AUTOSAR XML (schema 00045)
package /Dsm
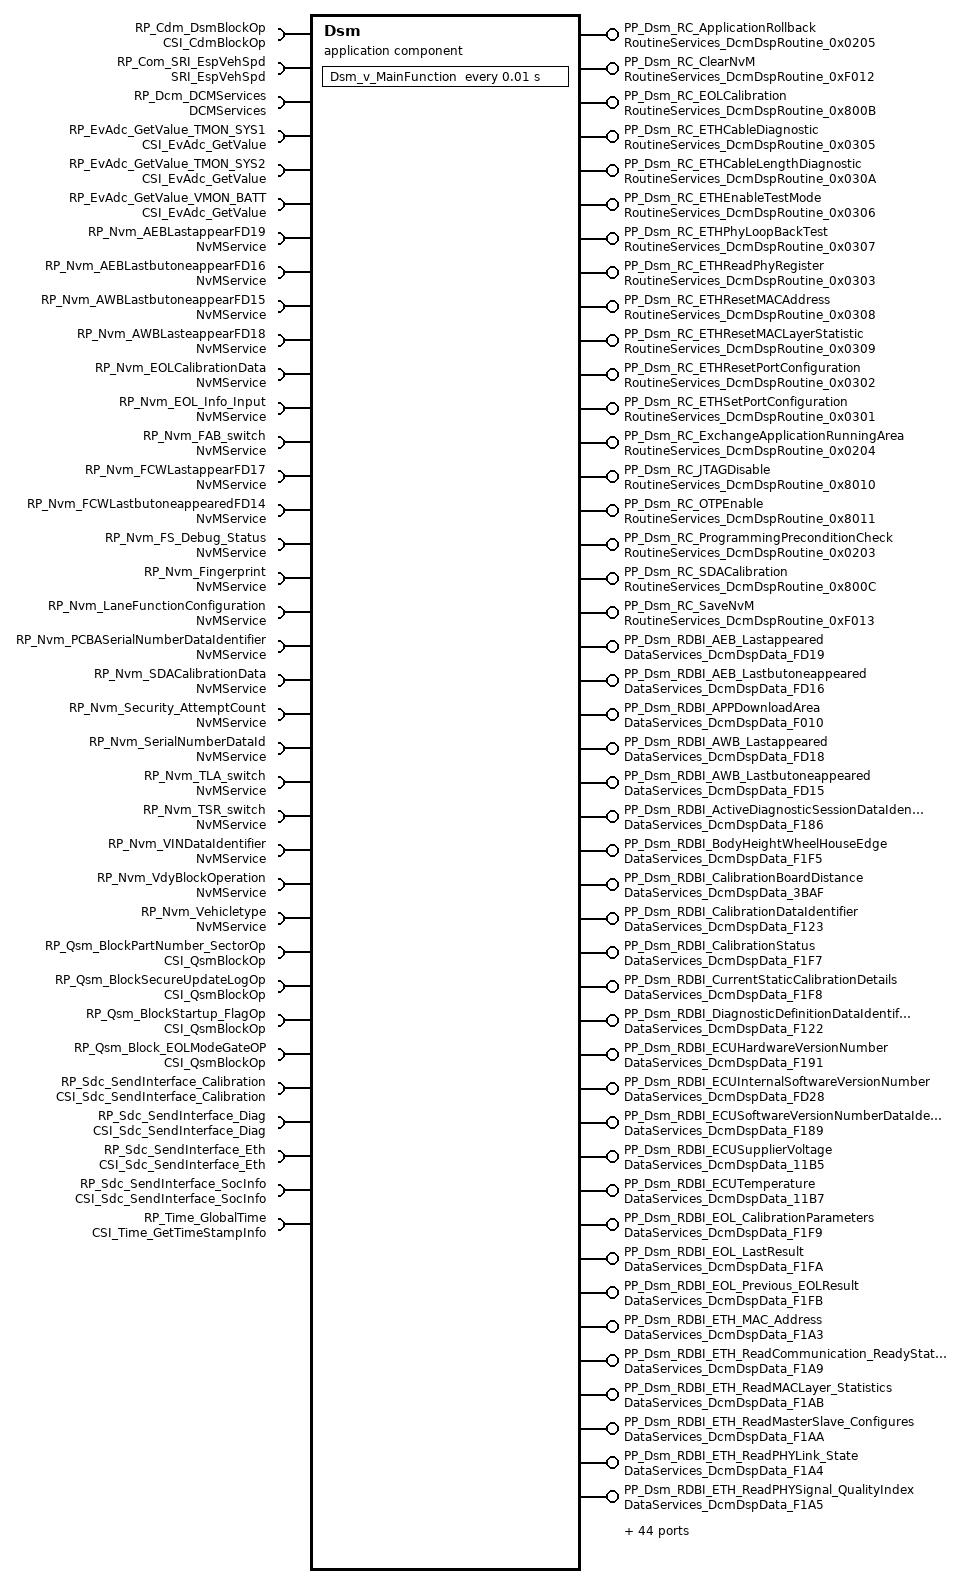
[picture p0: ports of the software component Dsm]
  application sw component type Dsm  # Diagnostic Service Management
    88 x provide port:
      PP_Dsm_RC_ApplicationRollback: provided-interface=RoutineServices_DcmDspRoutine_0x0205
      PP_Dsm_RC_ClearNvM: provided-interface=RoutineServices_DcmDspRoutine_0xF012
      PP_Dsm_RC_EOLCalibration: provided-interface=RoutineServices_DcmDspRoutine_0x800B
      PP_Dsm_RC_ETHCableDiagnostic: provided-interface=RoutineServices_DcmDspRoutine_0x0305
      PP_Dsm_RC_ETHCableLengthDiagnostic: provided-interface=RoutineServices_DcmDspRoutine_0x030A
      PP_Dsm_RC_ETHEnableTestMode: provided-interface=RoutineServices_DcmDspRoutine_0x0306
      PP_Dsm_RC_ETHPhyLoopBackTest: provided-interface=RoutineServices_DcmDspRoutine_0x0307
      PP_Dsm_RC_ETHReadPhyRegister: provided-interface=RoutineServices_DcmDspRoutine_0x0303
      PP_Dsm_RC_ETHResetMACAddress: provided-interface=RoutineServices_DcmDspRoutine_0x0308
      PP_Dsm_RC_ETHResetMACLayerStatistic: provided-interface=RoutineServices_DcmDspRoutine_0x0309
      PP_Dsm_RC_ETHResetPortConfiguration: provided-interface=RoutineServices_DcmDspRoutine_0x0302
      PP_Dsm_RC_ETHSetPortConfiguration: provided-interface=RoutineServices_DcmDspRoutine_0x0301
      PP_Dsm_RC_ExchangeApplicationRunningArea: provided-interface=RoutineServices_DcmDspRoutine_0x0204
      PP_Dsm_RC_JTAGDisable: provided-interface=RoutineServices_DcmDspRoutine_0x8010
      PP_Dsm_RC_OTPEnable: provided-interface=RoutineServices_DcmDspRoutine_0x8011
      PP_Dsm_RC_ProgrammingPreconditionCheck: provided-interface=RoutineServices_DcmDspRoutine_0x0203
      PP_Dsm_RC_SDACalibration: provided-interface=RoutineServices_DcmDspRoutine_0x800C
      PP_Dsm_RC_SaveNvM: provided-interface=RoutineServices_DcmDspRoutine_0xF013
      PP_Dsm_RDBI_AEB_Lastappeared: provided-interface=DataServices_DcmDspData_FD19
      PP_Dsm_RDBI_AEB_Lastbutoneappeared: provided-interface=DataServices_DcmDspData_FD16
      PP_Dsm_RDBI_APPDownloadArea: provided-interface=DataServices_DcmDspData_F010
      PP_Dsm_RDBI_AWB_Lastappeared: provided-interface=DataServices_DcmDspData_FD18
      PP_Dsm_RDBI_AWB_Lastbutoneappeared: provided-interface=DataServices_DcmDspData_FD15
      PP_Dsm_RDBI_ActiveDiagnosticSessionDataIdentifier: provided-interface=DataServices_DcmDspData_F186
      PP_Dsm_RDBI_BodyHeightWheelHouseEdge: provided-interface=DataServices_DcmDspData_F1F5
      PP_Dsm_RDBI_CalibrationBoardDistance: provided-interface=DataServices_DcmDspData_3BAF
      PP_Dsm_RDBI_CalibrationDataIdentifier: provided-interface=DataServices_DcmDspData_F123
      PP_Dsm_RDBI_CalibrationStatus: provided-interface=DataServices_DcmDspData_F1F7
      PP_Dsm_RDBI_CurrentStaticCalibrationDetails: provided-interface=DataServices_DcmDspData_F1F8
      PP_Dsm_RDBI_DiagnosticDefinitionDataIdentifier: provided-interface=DataServices_DcmDspData_F122
      PP_Dsm_RDBI_ECUHardwareVersionNumber: provided-interface=DataServices_DcmDspData_F191
      PP_Dsm_RDBI_ECUInternalSoftwareVersionNumber: provided-interface=DataServices_DcmDspData_FD28
      PP_Dsm_RDBI_ECUSoftwareVersionNumberDataIdentifier: provided-interface=DataServices_DcmDspData_F189
      PP_Dsm_RDBI_ECUSupplierVoltage: provided-interface=DataServices_DcmDspData_11B5
      PP_Dsm_RDBI_ECUTemperature: provided-interface=DataServices_DcmDspData_11B7
      PP_Dsm_RDBI_EOL_CalibrationParameters: provided-interface=DataServices_DcmDspData_F1F9
      PP_Dsm_RDBI_EOL_LastResult: provided-interface=DataServices_DcmDspData_F1FA
      PP_Dsm_RDBI_EOL_Previous_EOLResult: provided-interface=DataServices_DcmDspData_F1FB
      PP_Dsm_RDBI_ETH_MAC_Address: provided-interface=DataServices_DcmDspData_F1A3
      PP_Dsm_RDBI_ETH_ReadCommunication_ReadyStatus: provided-interface=DataServices_DcmDspData_F1A9
      PP_Dsm_RDBI_ETH_ReadMACLayer_Statistics: provided-interface=DataServices_DcmDspData_F1AB
      PP_Dsm_RDBI_ETH_ReadMasterSlave_Configures: provided-interface=DataServices_DcmDspData_F1AA
      PP_Dsm_RDBI_ETH_ReadPHYLink_State: provided-interface=DataServices_DcmDspData_F1A4
      PP_Dsm_RDBI_ETH_ReadPHYSignal_QualityIndex: provided-interface=DataServices_DcmDspData_F1A5
      PP_Dsm_RDBI_ETH_ReadPort_Configuration: provided-interface=DataServices_DcmDspData_F1A8
      PP_Dsm_RDBI_ETH_Read_NumberOfPorts: provided-interface=DataServices_DcmDspData_F1A7
      PP_Dsm_RDBI_FBLRequirementSpecification: provided-interface=DataServices_DcmDspData_F171
      PP_Dsm_RDBI_FBLVersionInformation: provided-interface=DataServices_DcmDspData_F170
      PP_Dsm_RDBI_FCW_Lastappeared: provided-interface=DataServices_DcmDspData_FD17
      PP_Dsm_RDBI_FCW_Lastbutoneappeared: provided-interface=DataServices_DcmDspData_FD14
      PP_Dsm_RDBI_FunctionSpecificationDataIdentifier: provided-interface=DataServices_DcmDspData_F121
      PP_Dsm_RDBI_ImagerTemperature: provided-interface=DataServices_DcmDspData_FD25
      PP_Dsm_RDBI_InternalSocTemperature: provided-interface=DataServices_DcmDspData_FD1E
      PP_Dsm_RDBI_InvalidAttemptCounter: provided-interface=DataServices_DcmDspData_0103
      PP_Dsm_RDBI_MCU_AbankError: provided-interface=DataServices_DcmDspData_FD26
      PP_Dsm_RDBI_MCU_BbankError: provided-interface=DataServices_DcmDspData_FD27
      PP_Dsm_RDBI_NetworkInformationDataIdentifier: provided-interface=DataServices_DcmDspData_F120
      PP_Dsm_RDBI_OMCalibrationStatus: provided-interface=DataServices_DcmDspData_FD20
      PP_Dsm_RDBI_OMSN: provided-interface=DataServices_DcmDspData_FD22
      PP_Dsm_RDBI_ProjectID: provided-interface=DataServices_DcmDspData_FD21
      PP_Dsm_RDBI_SDA_LastResults: provided-interface=DataServices_DcmDspData_F1FC
      PP_Dsm_RDBI_SecureUpdateLog: provided-interface=DataServices_DcmDspData_FEC0
      PP_Dsm_RDBI_SocBootSensor: provided-interface=DataServices_DcmDspData_FD23
      PP_Dsm_RDBI_SocSoftwareNumberDataIdentifier: provided-interface=DataServices_DcmDspData_FD29
      PP_Dsm_RDBI_SocSoftwareVersion: provided-interface=DataServices_DcmDspData_FD1F
      PP_Dsm_RDBI_SocSupplierSoftwareNumber: provided-interface=DataServices_DcmDspData_F194
      PP_Dsm_RDBI_SoftwareNumber: provided-interface=DataServices_DcmDspData_F188
      PP_Dsm_RDBI_applicationSoftwareFingerprintDataIdentifier: provided-interface=DataServices_DcmDspData_F184
      PP_Dsm_RWDBI_ECUHardwareVersionNumberDataIdentifier: provided-interface=DataServices_DcmDspData_F089
      PP_Dsm_RWDBI_ECUSerialNumberDataIdentifier: provided-interface=DataServices_DcmDspData_F18C
      PP_Dsm_RWDBI_EOL_ModeGate: provided-interface=DataServices_DcmDspData_F1FF
      PP_Dsm_RWDBI_EcuOperationMode: provided-com-specs=[{operation=ReadData, queue-length=1}, {operation=WriteData, queue-length=1}], provided-interface=DataServices_DcmDspData_F1FD
      PP_Dsm_RWDBI_FABSwitch: provided-interface=DataServices_DcmDspData_F1F1
      PP_Dsm_RWDBI_Fusa_Debug_Statua: provided-interface=DataServices_DcmDspData_FD2A
      PP_Dsm_RWDBI_InternalTestMode: provided-interface=DataServices_DcmDspData_FDFF
      PP_Dsm_RWDBI_LaneFunctionConfiguration: provided-interface=DataServices_DcmDspData_F1FE
      PP_Dsm_RWDBI_PCBASerialNumberDataIdentifier: provided-interface=DataServices_DcmDspData_FD24
      PP_Dsm_RWDBI_PartNumberDataIdentifier: provided-interface=DataServices_DcmDspData_F187
      PP_Dsm_RWDBI_SocResetControl: provided-interface=DataServices_DcmDspData_FD00
      PP_Dsm_RWDBI_SystemSupplierIdentifier: provided-interface=DataServices_DcmDspData_F18A
      PP_Dsm_RWDBI_TLASwitch: provided-interface=DataServices_DcmDspData_F1F3
      PP_Dsm_RWDBI_TSRSwitch: provided-interface=DataServices_DcmDspData_F1F2
      PP_Dsm_RWDBI_VINDataIdentifier: provided-interface=DataServices_DcmDspData_F190
      PP_Dsm_RWDBI_VehicleType: provided-interface=DataServices_DcmDspData_F1F0
      PP_Dsm_SRI_InternalTestMode: provided-interface=SRI_InternalTestMode
      PP_Dsm_SRI_SocResetControlState: provided-interface=SRI_DsmSocResetcontrolState
      PP_Dsm_SecurityAccess_SA_Level1: provided-interface=SecurityAccess_SA_Level1
      PP_Dsm_ServiceRequestSupplierNotification: provided-interface=ServiceRequestNotification
    36 x require port:
      RP_Cdm_DsmBlockOp: required-interface=CSI_CdmBlockOp
      RP_Com_SRI_EspVehSpd: nonqueued-receiver-com-spec=data-element=DE_EspVehSpd, required-interface=SRI_EspVehSpd
      RP_Dcm_DCMServices: required-interface=DCMServices
      RP_EvAdc_GetValue_TMON_SYS1: required-com-specs=[GetRegValue, GetPhyValue], required-interface=CSI_EvAdc_GetValue
      RP_EvAdc_GetValue_TMON_SYS2: required-com-specs=[GetRegValue, GetPhyValue], required-interface=CSI_EvAdc_GetValue
      RP_EvAdc_GetValue_VMON_BATT: required-com-specs=[GetRegValue, GetPhyValue], required-interface=CSI_EvAdc_GetValue
      RP_Nvm_AEBLastappearFD19: required-interface=NvMService
      RP_Nvm_AEBLastbutoneappearFD16: required-interface=NvMService
      RP_Nvm_AWBLastbutoneappearFD15: required-interface=NvMService
      RP_Nvm_AWBLasteappearFD18: required-interface=NvMService
      RP_Nvm_EOLCalibrationData: required-interface=NvMService
      RP_Nvm_EOL_Info_Input: required-interface=NvMService
      RP_Nvm_FAB_switch: required-interface=NvMService
      RP_Nvm_FCWLastappearFD17: required-interface=NvMService
      RP_Nvm_FCWLastbutoneappearedFD14: required-interface=NvMService
      RP_Nvm_FS_Debug_Status: required-interface=NvMService
      RP_Nvm_Fingerprint: required-interface=NvMService
      RP_Nvm_LaneFunctionConfiguration: required-interface=NvMService
      RP_Nvm_PCBASerialNumberDataIdentifier: required-interface=NvMService
      RP_Nvm_SDACalibrationData: required-interface=NvMService
      RP_Nvm_Security_AttemptCount: required-interface=NvMService
      RP_Nvm_SerialNumberDataId: required-interface=NvMService
      RP_Nvm_TLA_switch: required-interface=NvMService
      RP_Nvm_TSR_switch: required-interface=NvMService
      RP_Nvm_VINDataIdentifier: required-interface=NvMService
      RP_Nvm_VdyBlockOperation: required-interface=NvMService
      RP_Nvm_Vehicletype: required-interface=NvMService
      RP_Qsm_BlockPartNumber_SectorOp: required-interface=CSI_QsmBlockOp
      RP_Qsm_BlockSecureUpdateLogOp: required-interface=CSI_QsmBlockOp
      RP_Qsm_BlockStartup_FlagOp: required-interface=CSI_QsmBlockOp
      RP_Qsm_Block_EOLModeGateOP: required-interface=CSI_QsmBlockOp
      RP_Sdc_SendInterface_Calibration: required-interface=CSI_Sdc_SendInterface_Calibration
      RP_Sdc_SendInterface_Diag: required-interface=CSI_Sdc_SendInterface_Diag
      RP_Sdc_SendInterface_Eth: required-interface=CSI_Sdc_SendInterface_Eth
      RP_Sdc_SendInterface_SocInfo: required-interface=CSI_Sdc_SendInterface_SocInfo
      RP_Time_GlobalTime: required-interface=CSI_Time_GetTimeStampInfo
    behavior Dsm_IB: handle-termination-and-restart=NO-SUPPORT
      exclusive area DSM_EXCLUSIVEAREA
      init event IE_Dsm_v_Init: start-on-event=Dsm_v_Init
      timing event TE_Dsm_MainFunction: start-on-event=Dsm_v_MainFunction, period=0.01
      124 x operation invoked event:
        oie_PP_Dsm_RC_ApplicationRollback_Start: start-on-event=Dsm_u_RC_ApplicationRollback_StartRoutine, operation=PP_Dsm_RC_ApplicationRollback.Start
        oie_PP_Dsm_RC_ClearNvM_RequestResults: start-on-event=Dsm_u_RC_ClearNvM_RequestRoutineResults, operation=PP_Dsm_RC_ClearNvM.RequestResults
        oie_PP_Dsm_RC_ClearNvM_Start: start-on-event=Dsm_u_RC_ClearNvM_StartRoutine, operation=PP_Dsm_RC_ClearNvM.Start
        oie_PP_Dsm_RC_EOLCalibration_RequestResults: start-on-event=Dsm_u_RC_EOLCalibration_RequestRoutineResults, operation=PP_Dsm_RC_EOLCalibration.RequestResults
        oie_PP_Dsm_RC_EOLCalibration_Start: start-on-event=Dsm_u_RC_EOLCalibration_StartRoutine, operation=PP_Dsm_RC_EOLCalibration.Start
        oie_PP_Dsm_RC_ETHCableDiagnostic_RequestResults: start-on-event=Dsm_u_RC_ETHCableDiagnostic_RequestRoutineResults, operation=PP_Dsm_RC_ETHCableDiagnostic.RequestResults
        oie_PP_Dsm_RC_ETHCableDiagnostic_Start: start-on-event=Dsm_u_RC_ETHCableDiagnostic_StartRoutine, operation=PP_Dsm_RC_ETHCableDiagnostic.Start
        oie_PP_Dsm_RC_ETHCableLengthDiagnostic_RequestResults: start-on-event=Dsm_u_RC_ETHCableLengthDiagnostic_RequestRoutineResults, operation=PP_Dsm_RC_ETHCableLengthDiagnostic.RequestResults
        oie_PP_Dsm_RC_ETHCableLengthDiagnostic_Start: start-on-event=Dsm_u_RC_ETHCableLengthDiagnostic_StartRoutine, operation=PP_Dsm_RC_ETHCableLengthDiagnostic.Start
        oie_PP_Dsm_RC_ETHEnableTestMode_RequestResults: start-on-event=Dsm_u_RC_ETHEnableTestMode_RequestRoutineResults, operation=PP_Dsm_RC_ETHEnableTestMode.RequestResults
        oie_PP_Dsm_RC_ETHEnableTestMode_Start: start-on-event=Dsm_u_RC_ETHEnableTestMode_StartRoutine, operation=PP_Dsm_RC_ETHEnableTestMode.Start
        oie_PP_Dsm_RC_ETHEnableTestMode_Stop: start-on-event=Dsm_u_RC_ETHEnableTestMode_StopRoutine, operation=PP_Dsm_RC_ETHEnableTestMode.Stop
        oie_PP_Dsm_RC_ETHPhyLoopBackTest_RequestResults: start-on-event=Dsm_u_RC_ETHPhyLoopBackTest_RequestRoutineResults, operation=PP_Dsm_RC_ETHPhyLoopBackTest.RequestResults
        oie_PP_Dsm_RC_ETHPhyLoopBackTest_Start: start-on-event=Dsm_u_RC_ETHPhyLoopBackTest_StartRoutine, operation=PP_Dsm_RC_ETHPhyLoopBackTest.Start
        oie_PP_Dsm_RC_ETHPhyLoopBackTest_Stop: start-on-event=Dsm_u_RC_ETHPhyLoopBackTest_StopRoutine, operation=PP_Dsm_RC_ETHPhyLoopBackTest.Stop
        oie_PP_Dsm_RC_ETHReadPhyRegister_RequestResults: start-on-event=Dsm_u_RC_ETHReadPhyRegister_RequestRoutineResults, operation=PP_Dsm_RC_ETHReadPhyRegister.RequestResults
        oie_PP_Dsm_RC_ETHReadPhyRegister_Start: start-on-event=Dsm_u_RC_ETHReadPhyRegister_StartRoutine, operation=PP_Dsm_RC_ETHReadPhyRegister.Start
        oie_PP_Dsm_RC_ETHResetMACAddress_RequestResults: start-on-event=Dsm_u_RC_ETHResetMACAddress_RequestRoutineResults, operation=PP_Dsm_RC_ETHResetMACAddress.RequestResults
        oie_PP_Dsm_RC_ETHResetMACAddress_Start: start-on-event=Dsm_u_RC_ETHResetMACAddress_StartRoutine, operation=PP_Dsm_RC_ETHResetMACAddress.Start
        oie_PP_Dsm_RC_ETHResetMACLayerStatistic_RequestResults: start-on-event=Dsm_u_RC_ETHResetMACLayerStatistic_RequestRoutineResults, operation=PP_Dsm_RC_ETHResetMACLayerStatistic.RequestResults
        oie_PP_Dsm_RC_ETHResetMACLayerStatistic_Start: start-on-event=Dsm_u_RC_ETHResetMACLayerStatistic_StartRoutine, operation=PP_Dsm_RC_ETHResetMACLayerStatistic.Start
        oie_PP_Dsm_RC_ETHResetPortConfiguration_RequestResults: start-on-event=Dsm_u_RC_ETHResetPortConfiguration_RequestRoutineResults, operation=PP_Dsm_RC_ETHResetPortConfiguration.RequestResults
        oie_PP_Dsm_RC_ETHResetPortConfiguration_Start: start-on-event=Dsm_u_RC_ETHResetPortConfiguration_StartRoutine, operation=PP_Dsm_RC_ETHResetPortConfiguration.Start
        oie_PP_Dsm_RC_ETHSetPortConfiguration_RequestResults: start-on-event=Dsm_u_RC_ETHSetPortConfiguration_RequestRoutineResults, operation=PP_Dsm_RC_ETHSetPortConfiguration.RequestResults
        oie_PP_Dsm_RC_ETHSetPortConfiguration_Start: start-on-event=Dsm_u_RC_ETHSetPortConfiguration_StartRoutine, operation=PP_Dsm_RC_ETHSetPortConfiguration.Start
        oie_PP_Dsm_RC_ExchangeApplicationRunningArea_Start: start-on-event=Dsm_u_RC_ExchangeApplicationRunningArea_StartRoutine, operation=PP_Dsm_RC_ExchangeApplicationRunningArea.Start
        oie_PP_Dsm_RC_LockJTAG_RequestResults: start-on-event=Dsm_u_RC_LockJTAG_RequestRoutineResults, operation=PP_Dsm_RC_JTAGDisable.RequestResults
        oie_PP_Dsm_RC_LockJTAG_Start: start-on-event=Dsm_u_RC_LockJTAG_StartRoutine, operation=PP_Dsm_RC_JTAGDisable.Start
        oie_PP_Dsm_RC_OTPEnable_RequestResults: start-on-event=Dsm_u_RC_OTPEnable_RequestRoutineResults, operation=PP_Dsm_RC_OTPEnable.RequestResults
        oie_PP_Dsm_RC_OTPEnable_Start: start-on-event=Dsm_u_RC_OTPEnable_StartRoutine, operation=PP_Dsm_RC_OTPEnable.Start
        oie_PP_Dsm_RC_ProgrammingPreconditionCheck_Start: start-on-event=Dsm_u_RC_ProgrammingPreconditionCheck_StartRoutine, operation=PP_Dsm_RC_ProgrammingPreconditionCheck.Start
        oie_PP_Dsm_RC_SDACalibration_RequestResults: start-on-event=Dsm_u_RC_SDACalibration_RequestRoutineResults, operation=PP_Dsm_RC_SDACalibration.RequestResults
        oie_PP_Dsm_RC_SDACalibration_Start: start-on-event=Dsm_u_RC_SDACalibration_StartRoutine, operation=PP_Dsm_RC_SDACalibration.Start
        oie_PP_Dsm_RC_SaveNvM_RequestResults: start-on-event=Dsm_u_RC_SaveNvM_RequestRoutineResults, operation=PP_Dsm_RC_SaveNvM.RequestResults
        oie_PP_Dsm_RC_SaveNvM_Start: start-on-event=Dsm_u_RC_SaveNvM_StartRoutine, operation=PP_Dsm_RC_SaveNvM.Start
        oie_PP_Dsm_RDBI_AEB_Lastappeared_ReadData: start-on-event=Dsm_u_RDBI_AEB_Lastappeared_Read, operation=PP_Dsm_RDBI_AEB_Lastappeared.ReadData
        oie_PP_Dsm_RDBI_AEB_Lastbutoneappeared_ReadData: start-on-event=Dsm_u_RDBI_AEB_Lastbutoneappeared_Read, operation=PP_Dsm_RDBI_AEB_Lastbutoneappeared.ReadData
        oie_PP_Dsm_RDBI_APPDownloadArea_ConditionCheckRead: start-on-event=Dsm_u_RDBI_APPDownloadArea_ConditionCheck, operation=PP_Dsm_RDBI_APPDownloadArea.ConditionCheckRead
        oie_PP_Dsm_RDBI_APPDownloadArea_ReadData: start-on-event=Dsm_u_RDBI_APPDownloadArea_Read, operation=PP_Dsm_RDBI_APPDownloadArea.ReadData
        oie_PP_Dsm_RDBI_APPFingerprint_ReadData: start-on-event=Dsm_u_RDBI_applicationSoftwareFingerprintDataIdentifier_Read, operation=PP_Dsm_RDBI_applicationSoftwareFingerprintDataIdentifier.ReadData
        oie_PP_Dsm_RDBI_AWB_Lastappeared_ReadData: start-on-event=Dsm_u_RDBI_AWB_Lastappeared_Read, operation=PP_Dsm_RDBI_AWB_Lastappeared.ReadData
        oie_PP_Dsm_RDBI_AWB_Lastbutoneappeared_ReadData: start-on-event=Dsm_u_RDBI_AWB_Lastbutoneappeared_Read, operation=PP_Dsm_RDBI_AWB_Lastbutoneappeared.ReadData
        oie_PP_Dsm_RDBI_ActiveDiagnosticSessionDataIdentifier_ReadData: start-on-event=Dsm_u_RDBI_ActiveDiagnosticSessionDataIdentifier_Read, operation=PP_Dsm_RDBI_ActiveDiagnosticSessionDataIdentifier.ReadData
        oie_PP_Dsm_RDBI_BodyHeightWheelHouseEdge_ReadData: start-on-event=Dsm_u_RDBI_BodyHeightWheelHouseEdge_Read, operation=PP_Dsm_RDBI_BodyHeightWheelHouseEdge.ReadData
        oie_PP_Dsm_RDBI_CalibrationBoardDistance_ReadData: start-on-event=Dsm_u_RDBI_CalibrationBoardDistance_Read, operation=PP_Dsm_RDBI_CalibrationBoardDistance.ReadData
        oie_PP_Dsm_RDBI_CalibrationDataIdentifier_ReadData: start-on-event=Dsm_u_RDBI_CalibrationDataIdentifier_Read, operation=PP_Dsm_RDBI_CalibrationDataIdentifier.ReadData
        oie_PP_Dsm_RDBI_CalibrationStatus_ReadData: start-on-event=Dsm_u_RDBI_CalibrationStatus_Read, operation=PP_Dsm_RDBI_CalibrationStatus.ReadData
        oie_PP_Dsm_RDBI_CurrentStaticCalibrationDetails_ReadData: start-on-event=Dsm_u_RDBI_CurrentStaticCalibrationDetails_Read, operation=PP_Dsm_RDBI_CurrentStaticCalibrationDetails.ReadData
        oie_PP_Dsm_RDBI_DiagnosticDefinitionDataIdentifier_ReadData: start-on-event=Dsm_u_RDBI_DiagnosticDefinitionDataIdentifier_Read, operation=PP_Dsm_RDBI_DiagnosticDefinitionDataIdentifier.ReadData
        oie_PP_Dsm_RDBI_ECUHardwareVersionNumberDataIdentifier_ReadData: start-on-event=Dsm_u_RDBI_ECUHardwareVersionNumberDataIdentifier_Read, operation=PP_Dsm_RWDBI_ECUHardwareVersionNumberDataIdentifier.ReadData
        oie_PP_Dsm_RDBI_ECUHardwareVersionNumberDataIdentifier_WriteData: start-on-event=Dsm_u_WDBI_ECUHardwareVersionNumberDataIdentifier_Write, operation=PP_Dsm_RWDBI_ECUHardwareVersionNumberDataIdentifier.WriteData
        oie_PP_Dsm_RDBI_ECUHardwareVersionNumber_ReadData: start-on-event=Dsm_u_RDBI_ECUHardwareVersionNumber_Read, operation=PP_Dsm_RDBI_ECUHardwareVersionNumber.ReadData
        oie_PP_Dsm_RDBI_ECUInternalSoftwareVersionNumber_ReadData: start-on-event=Dsm_u_RDBI_ECUInternalSoftwareVersionNumber_Read, operation=PP_Dsm_RDBI_ECUInternalSoftwareVersionNumber.ReadData
        oie_PP_Dsm_RDBI_ECUPartNumber_ReadData: start-on-event=Dsm_u_RDBI_PartNumberDataIdentifier_Read, operation=PP_Dsm_RWDBI_PartNumberDataIdentifier.ReadData
        oie_PP_Dsm_RDBI_ECUSoftwareVersionNumberDataIdentifier_ReadData: start-on-event=Dsm_u_RDBI_ECUSoftwareVersionNumberDataIdentifier_Read, operation=PP_Dsm_RDBI_ECUSoftwareVersionNumberDataIdentifier.ReadData
        oie_PP_Dsm_RDBI_ECUSupplierVoltage_ReadData: start-on-event=Dsm_u_RDBI_ECUSupplierVoltage_Read, operation=PP_Dsm_RDBI_ECUSupplierVoltage.ReadData
        oie_PP_Dsm_RDBI_ECUTemperature_ReadData: start-on-event=Dsm_u_RDBI_ECUTemperature_Read, operation=PP_Dsm_RDBI_ECUTemperature.ReadData
        oie_PP_Dsm_RDBI_EOL_CalibrationParameters_ReadData: start-on-event=Dsm_u_RDBI_EOL_CalibrationParameters_Read, operation=PP_Dsm_RDBI_EOL_CalibrationParameters.ReadData
        oie_PP_Dsm_RDBI_EOL_LastResult_ReadData: start-on-event=Dsm_u_RDBI_EOL_LastResult_Read, operation=PP_Dsm_RDBI_EOL_LastResult.ReadData
        oie_PP_Dsm_RDBI_EOL_Previous_EOLResult_ReadData: start-on-event=Dsm_u_RDBI_EOL_Previous_EOLResult_Read, operation=PP_Dsm_RDBI_EOL_Previous_EOLResult.ReadData
        oie_PP_Dsm_RDBI_ETH_MAC_Address_ReadData: start-on-event=Dsm_u_RDBI_ETH_MAC_Address_Read, operation=PP_Dsm_RDBI_ETH_MAC_Address.ReadData
        oie_PP_Dsm_RDBI_ETH_ReadCommunication_ReadyStatus_ReadData: start-on-event=Dsm_u_RDBI_ETH_ReadCommunication_ReadyStatus_Read, operation=PP_Dsm_RDBI_ETH_ReadCommunication_ReadyStatus.ReadData
        oie_PP_Dsm_RDBI_ETH_ReadMACLayer_Statistics_ReadData: start-on-event=Dsm_u_RDBI_ETH_ReadMACLayer_Statistics_Read, operation=PP_Dsm_RDBI_ETH_ReadMACLayer_Statistics.ReadData
        oie_PP_Dsm_RDBI_ETH_ReadMasterSlave_Configures_ReadData: start-on-event=Dsm_u_RDBI_ETH_ReadMasterSlave_Configures_Read, operation=PP_Dsm_RDBI_ETH_ReadMasterSlave_Configures.ReadData
        oie_PP_Dsm_RDBI_ETH_ReadPHYLink_State_ReadData: start-on-event=Dsm_u_RDBI_ETH_ReadPHYLink_State_Read, operation=PP_Dsm_RDBI_ETH_ReadPHYLink_State.ReadData
        oie_PP_Dsm_RDBI_ETH_ReadPHYSignal_QualityIndex_ReadData: start-on-event=Dsm_u_RDBI_ETH_ReadPHYSignal_QualityIndex_Read, operation=PP_Dsm_RDBI_ETH_ReadPHYSignal_QualityIndex.ReadData
        oie_PP_Dsm_RDBI_ETH_ReadPort_Configuration_ReadData: start-on-event=Dsm_u_RDBI_ETH_ReadPort_Configuration_Read, operation=PP_Dsm_RDBI_ETH_ReadPort_Configuration.ReadData
        oie_PP_Dsm_RDBI_ETH_Read_NumberOfPorts_ReadData: start-on-event=Dsm_u_RDBI_ETH_Read_NumberOfPorts_Read, operation=PP_Dsm_RDBI_ETH_Read_NumberOfPorts.ReadData
        oie_PP_Dsm_RDBI_FBLRequirementSpecification_ReadData: start-on-event=Dsm_u_RDBI_FBLRequirementSpecification_Read, operation=PP_Dsm_RDBI_FBLRequirementSpecification.ReadData
        oie_PP_Dsm_RDBI_FBLVersionInformation_ReadData: start-on-event=Dsm_u_RDBI_FBLVersionInformation_Read, operation=PP_Dsm_RDBI_FBLVersionInformation.ReadData
        oie_PP_Dsm_RDBI_FCW_Lastappeared_ReadData: start-on-event=Dsm_u_RDBI_FCW_Lastappeared_Read, operation=PP_Dsm_RDBI_FCW_Lastappeared.ReadData
        oie_PP_Dsm_RDBI_FCW_Lastbutoneappeared_ReadData: start-on-event=Dsm_u_RDBI_FCW_Lastbutoneappeared_Read, operation=PP_Dsm_RDBI_FCW_Lastbutoneappeared.ReadData
        oie_PP_Dsm_RDBI_FunctionSpecificationDataIdentifier_ReadData: start-on-event=Dsm_u_RDBI_FunctionSpecificationDataIdentifier_Read, operation=PP_Dsm_RDBI_FunctionSpecificationDataIdentifier.ReadData
        oie_PP_Dsm_RDBI_ImagerTemperature_ReadData: start-on-event=Dsm_u_RDBI_ImagerTemperature_Read, operation=PP_Dsm_RDBI_ImagerTemperature.ReadData
        oie_PP_Dsm_RDBI_InternalSocTemperature_ReadData: start-on-event=Dsm_u_RDBI_InternalSocTemperature_Read, operation=PP_Dsm_RDBI_InternalSocTemperature.ReadData
        oie_PP_Dsm_RDBI_InvalidAttemptCounter_ReadData: start-on-event=Dsm_u_RDBI_InvalidAttemptCounter_Read, operation=PP_Dsm_RDBI_InvalidAttemptCounter.ReadData
        oie_PP_Dsm_RDBI_MCU_AbankError_ReadData: start-on-event=Dsm_u_RDBI_MCU_AbankError_Read, operation=PP_Dsm_RDBI_MCU_AbankError.ReadData
        oie_PP_Dsm_RDBI_MCU_BbankError_ReadData: start-on-event=Dsm_u_RDBI_MCU_BbankError_Read, operation=PP_Dsm_RDBI_MCU_BbankError.ReadData
        oie_PP_Dsm_RDBI_NetworkInformationDataIdentifier_ReadData: start-on-event=Dsm_u_RDBI_NetworkInformationDataIdentifier_Read, operation=PP_Dsm_RDBI_NetworkInformationDataIdentifier.ReadData
        oie_PP_Dsm_RDBI_OMCalibrationStatus_ReadData: start-on-event=Dsm_u_RDBI_OMCalibrationStatus_Read, operation=PP_Dsm_RDBI_OMCalibrationStatus.ReadData
        oie_PP_Dsm_RDBI_OMSN_ReadData: start-on-event=Dsm_u_RDBI_OMSN_Read, operation=PP_Dsm_RDBI_OMSN.ReadData
        oie_PP_Dsm_RDBI_ProjectID_ReadData: start-on-event=Dsm_u_RDBI_ProjectID_Read, operation=PP_Dsm_RDBI_ProjectID.ReadData
        oie_PP_Dsm_RDBI_SDA_LastResults_ReadData: start-on-event=Dsm_u_RDBI_SDA_LastResults_Read, operation=PP_Dsm_RDBI_SDA_LastResults.ReadData
        oie_PP_Dsm_RDBI_SecureUpdateLog_ReadData: start-on-event=Dsm_u_RDBI_SecureUpdateLog_Read, operation=PP_Dsm_RDBI_SecureUpdateLog.ReadData
        oie_PP_Dsm_RDBI_SocBootSensor_ReadData: start-on-event=Dsm_u_RDBI_SocBootSensor_Read, operation=PP_Dsm_RDBI_SocBootSensor.ReadData
        oie_PP_Dsm_RDBI_SocSoftwareNumberDataIdentifier_ReadData: start-on-event=Dsm_u_RDBI_SocSoftwareNumberDataIdentifier_Read, operation=PP_Dsm_RDBI_SocSoftwareNumberDataIdentifier.ReadData
        oie_PP_Dsm_RDBI_SocSoftwareVersion_ReadData: start-on-event=Dsm_u_RDBI_SocSoftwareVersion_Read, operation=PP_Dsm_RDBI_SocSoftwareVersion.ReadData
        oie_PP_Dsm_RDBI_SocSupplierSoftwareNumber_ReadData: start-on-event=Dsm_u_RDBI_SocSupplierSoftwareNumber_Read, operation=PP_Dsm_RDBI_SocSupplierSoftwareNumber.ReadData
        oie_PP_Dsm_RDBI_SoftwareNumber_ReadData: start-on-event=Dsm_u_RDBI_SoftwareNumber_Read, operation=PP_Dsm_RDBI_SoftwareNumber.ReadData
        oie_PP_Dsm_RDBI_VehicleType_ReadData: start-on-event=Dsm_u_RDBI_VehicleType_Read, operation=PP_Dsm_RWDBI_VehicleType.ReadData
        oie_PP_Dsm_RWDBI_ECUSerialNumberDataIdentifier_ReadData: start-on-event=Dsm_u_RDBI_ECUSerialNumberDataIdentifier_Read, operation=PP_Dsm_RWDBI_ECUSerialNumberDataIdentifier.ReadData
        oie_PP_Dsm_RWDBI_ECUSerialNumberDataIdentifier_WriteData: start-on-event=Dsm_u_WDBI_ECUSerialNumberDataIdentifier_Write, operation=PP_Dsm_RWDBI_ECUSerialNumberDataIdentifier.WriteData
        oie_PP_Dsm_RWDBI_EOL_ModeGate_ReadData: start-on-event=Dsm_u_RDBI_EOL_ModeGate_Read, operation=PP_Dsm_RWDBI_EOL_ModeGate.ReadData
        oie_PP_Dsm_RWDBI_EOL_ModeGate_WriteData: start-on-event=Dsm_u_WDBI_EOL_ModeGate_Write, operation=PP_Dsm_RWDBI_EOL_ModeGate.WriteData
        oie_PP_Dsm_RWDBI_EcuOperationMode_ReadData: start-on-event=Dsm_u_RDBI_ECUOperationMode_Read, operation=PP_Dsm_RWDBI_EcuOperationMode.ReadData
        oie_PP_Dsm_RWDBI_EcuOperationMode_WriteData: start-on-event=Dsm_u_WDBI_ECUOperationMode_Write, operation=PP_Dsm_RWDBI_EcuOperationMode.WriteData
        oie_PP_Dsm_RWDBI_FABSwitch_ReadData: start-on-event=Dsm_u_RDBI_FABSwitch_Read, operation=PP_Dsm_RWDBI_FABSwitch.ReadData
        oie_PP_Dsm_RWDBI_FABSwitch_WriteData: start-on-event=Dsm_u_WDBI_FABSwitch_Write, operation=PP_Dsm_RWDBI_FABSwitch.WriteData
        oie_PP_Dsm_RWDBI_Fusa_Debug_Statua_ReadData: start-on-event=Dsm_u_RDBI_Fusa_Debug_Status_Read, operation=PP_Dsm_RWDBI_Fusa_Debug_Statua.ReadData
        oie_PP_Dsm_RWDBI_Fusa_Debug_Statua_WriteData: start-on-event=Dsm_u_WDBI_Fusa_Debug_Status_Write, operation=PP_Dsm_RWDBI_Fusa_Debug_Statua.WriteData
        oie_PP_Dsm_RWDBI_InternalTestMode_ReadData: start-on-event=Dsm_u_RDBI_InternalTestMode_Read, operation=PP_Dsm_RWDBI_InternalTestMode.ReadData
        oie_PP_Dsm_RWDBI_InternalTestMode_WriteData: start-on-event=Dsm_u_WDBI_InternalTestMode_Write, operation=PP_Dsm_RWDBI_InternalTestMode.WriteData
        oie_PP_Dsm_RWDBI_LaneFunctionConfiguration_ReadData: start-on-event=Dsm_u_RDBI_LaneFunctionConfiguration_Read, operation=PP_Dsm_RWDBI_LaneFunctionConfiguration.ReadData
        oie_PP_Dsm_RWDBI_LaneFunctionConfiguration_WriteData: start-on-event=Dsm_u_WDBI_LaneFunctionConfiguration_Write, operation=PP_Dsm_RWDBI_LaneFunctionConfiguration.WriteData
        oie_PP_Dsm_RWDBI_PCBASerialNumberDataIdentifier_ReadData: start-on-event=Dsm_u_RDBI_PCBASerialNumberDataIdentifier_Read, operation=PP_Dsm_RWDBI_PCBASerialNumberDataIdentifier.ReadData
        oie_PP_Dsm_RWDBI_PCBASerialNumberDataIdentifier_WriteData: start-on-event=Dsm_u_WDBI_PCBASerialNumberDataIdentifier_Write, operation=PP_Dsm_RWDBI_PCBASerialNumberDataIdentifier.WriteData
        oie_PP_Dsm_RWDBI_PartNumberDataIdentifier_WriteData: start-on-event=Dsm_u_WDBI_PartNumberDataIdentifier_Write, operation=PP_Dsm_RWDBI_PartNumberDataIdentifier.WriteData
        oie_PP_Dsm_RWDBI_SocResetControl_ReadData: start-on-event=Dsm_u_RDBI_SocResetControl_Read, operation=PP_Dsm_RWDBI_SocResetControl.ReadData
        oie_PP_Dsm_RWDBI_SocResetControl_WriteData: start-on-event=Dsm_u_WDBI_SocResetControl_Write, operation=PP_Dsm_RWDBI_SocResetControl.WriteData
        oie_PP_Dsm_RWDBI_SystemSupplierIdentifier_ReadData: start-on-event=Dsm_u_RDBI_SystemSupplierIdentifier_Read, operation=PP_Dsm_RWDBI_SystemSupplierIdentifier.ReadData
        oie_PP_Dsm_RWDBI_SystemSupplierIdentifier_WriteData: start-on-event=Dsm_u_WDBI_SystemSupplierIdentifier_Write, operation=PP_Dsm_RWDBI_SystemSupplierIdentifier.WriteData
        oie_PP_Dsm_RWDBI_TLASwitch_ReadData: start-on-event=Dsm_u_RDBI_TLASwitch_Read, operation=PP_Dsm_RWDBI_TLASwitch.ReadData
        oie_PP_Dsm_RWDBI_TLASwitch_WriteData: start-on-event=Dsm_u_WDBI_TLASwitch_Write, operation=PP_Dsm_RWDBI_TLASwitch.WriteData
        oie_PP_Dsm_RWDBI_TSRSwitch_ReadData: start-on-event=Dsm_u_RDBI_TSRSwitch_Read, operation=PP_Dsm_RWDBI_TSRSwitch.ReadData
        oie_PP_Dsm_RWDBI_TSRSwitch_WriteData: start-on-event=Dsm_u_WDBI_TSRSwitch_Write, operation=PP_Dsm_RWDBI_TSRSwitch.WriteData
        oie_PP_Dsm_RWDBI_VINDataIdentifier_ReadData: start-on-event=Dsm_u_RDBI_VINDataIdentifier_Read, operation=PP_Dsm_RWDBI_VINDataIdentifier.ReadData
        oie_PP_Dsm_RWDBI_VINDataIdentifier_WriteData: start-on-event=Dsm_u_WDBI_VINDataIdentifier_Write, operation=PP_Dsm_RWDBI_VINDataIdentifier.WriteData
        oie_PP_Dsm_RWDBI_VehicleType_WriteData: start-on-event=Dsm_u_WDBI_VehicleType_Write, operation=PP_Dsm_RWDBI_VehicleType.WriteData
        oie_PP_Dsm_SecurityAccess_SA_Level1_CompareKey: start-on-event=Dsm_u_SA_Level1_CompareKey, operation=PP_Dsm_SecurityAccess_SA_Level1.CompareKey
        oie_PP_Dsm_SecurityAccess_SA_Level1_GetSecurityAttemptCounter: start-on-event=Dsm_u_SA_Level1_GetAttemptCounter, operation=PP_Dsm_SecurityAccess_SA_Level1.GetSecurityAttemptCounter
        oie_PP_Dsm_SecurityAccess_SA_Level1_GetSeed: start-on-event=Dsm_u_SA_Level1_GetSeed, operation=PP_Dsm_SecurityAccess_SA_Level1.GetSeed
        oie_PP_Dsm_SecurityAccess_SA_Level1_SetSecurityAttemptCounter: start-on-event=Dsm_u_SA_Level1_SetAttemptCounter, operation=PP_Dsm_SecurityAccess_SA_Level1.SetSecurityAttemptCounter
        oie_PP_Dsm_ServiceRequestSupplierNotification_Confirmation: start-on-event=Dsm_u_ServiceRequestSupplierNotification_Confirmation, operation=PP_Dsm_ServiceRequestSupplierNotification.Confirmation
        oie_PP_Dsm_ServiceRequestSupplierNotification_Indication: start-on-event=Dsm_u_ServiceRequestSupplierNotification_Indication, operation=PP_Dsm_ServiceRequestSupplierNotification.Indication
      explicit-inter-runnable-variables:
        data Dsm_IRV_InternalTestMode: type=uint8, init-value=0
        data Dsm_IRV_PreCondition_CheckState: type=boolean, init-value=FALSE
        data Dsm_IRV_SocResetControlState: type=uint8
      126 x runnable:
        Dsm_u_RC_ApplicationRollback_StartRoutine: can-enter-exclusive-area=DSM_EXCLUSIVEAREA
          sync call scp_Qsm_GetErrorStatues: operation=RP_Qsm_BlockStartup_FlagOp.Qsm_GetErrorStatues, timeout=0.0
          sync call scp_Qsm_ReadBlock: operation=RP_Qsm_BlockStartup_FlagOp.Qsm_ReadBlock, timeout=0.0
          sync call scp_Qsm_WriteBlock: operation=RP_Qsm_BlockStartup_FlagOp.Qsm_WriteBlock, timeout=0.0
        Dsm_u_RC_ClearNvM_RequestRoutineResults
          sync call scp_GetErrorStatus: operation=RP_Nvm_VdyBlockOperation.GetErrorStatus, timeout=0.0
        Dsm_u_RC_ClearNvM_StartRoutine
          sync call scp_WriteBlock: operation=RP_Nvm_VdyBlockOperation.WriteBlock, timeout=0.0
        Dsm_u_RC_EOLCalibration_RequestRoutineResults
          7 x sync call, all with timeout=0.0:
            scp_CalibrationFlag_Read: operation=RP_Sdc_SendInterface_Calibration.CalibrationFlag_Read
            scp_CameraCaliresultDetails_: operation=RP_Sdc_SendInterface_Calibration.CameraCaliresultDetails_Read
            scp_CameraValue_Read: operation=RP_Sdc_SendInterface_Calibration.CameraValue_Read
            scp_EOLCalResult_Read: operation=RP_Sdc_SendInterface_Calibration.EOLCalResult_Read
            scp_GetErrorStatus: operation=RP_Nvm_EOLCalibrationData.GetErrorStatus
            scp_SetRamBlockStatus: operation=RP_Nvm_EOLCalibrationData.SetRamBlockStatus
            scp_WriteBlock: operation=RP_Nvm_EOLCalibrationData.WriteBlock
        Dsm_u_RC_EOLCalibration_StartRoutine
          5 x sync call, all with timeout=0.0:
            scp_GetErrorStatus: operation=RP_Nvm_EOL_Info_Input.GetErrorStatus
            scp_RequestEOLCalibration: operation=RP_Sdc_SendInterface_Calibration.RequestEOLCalibration
            scp_SetRamBlockStatus: operation=RP_Nvm_EOL_Info_Input.SetRamBlockStatus
            scp_SocSysState_Read: operation=RP_Sdc_SendInterface_Diag.SocSysState_Read
            scp_WriteBlock: operation=RP_Nvm_EOL_Info_Input.WriteBlock
        Dsm_u_RC_ETHCableDiagnostic_RequestRoutineResults
          sync call scp_EthCableDiagnosticInfo_R: operation=RP_Sdc_SendInterface_Eth.EthCableDiagnosticInfo_Read, timeout=0.0
        Dsm_u_RC_ETHCableDiagnostic_StartRoutine
          sync call scp_EthCableDiagnostic_Start: operation=RP_Sdc_SendInterface_Eth.EthCableDiagnostic_StartRoutine, timeout=0.0
        Dsm_u_RC_ETHCableLengthDiagnostic_RequestRoutineResults
          sync call scp_EthCableLengthDiagnostic: operation=RP_Sdc_SendInterface_Eth.EthCableLengthDiagnosticInfo_Read, timeout=0.0
        Dsm_u_RC_ETHCableLengthDiagnostic_StartRoutine
          sync call scp_EthCableLengthDiagnostic: operation=RP_Sdc_SendInterface_Eth.EthCableLengthDiagnostic_StartRoutine, timeout=0.0
        Dsm_u_RC_ETHEnableTestMode_RequestRoutineResults
          sync call scp_EthEnableTestModeInfo_Re: operation=RP_Sdc_SendInterface_Eth.EthEnableTestModeInfo_Read, timeout=0.0
        Dsm_u_RC_ETHEnableTestMode_StartRoutine
          sync call scp_EthEnableTestMode_StartR: operation=RP_Sdc_SendInterface_Eth.EthEnableTestMode_StartRoutine, timeout=0.0
        Dsm_u_RC_ETHEnableTestMode_StopRoutine
          sync call scp_EthEnableTestMode_StopRo: operation=RP_Sdc_SendInterface_Eth.EthEnableTestMode_StopRoutine, timeout=0.0
        Dsm_u_RC_ETHPhyLoopBackTest_RequestRoutineResults
          sync call scp_EthPhyLoopBackTestInfo_R: operation=RP_Sdc_SendInterface_Eth.EthPhyLoopBackTestInfo_Read, timeout=0.0
        Dsm_u_RC_ETHPhyLoopBackTest_StartRoutine
          sync call scp_EthPhyLoopBackTest_Start: operation=RP_Sdc_SendInterface_Eth.EthPhyLoopBackTest_StartRoutine, timeout=0.0
        Dsm_u_RC_ETHPhyLoopBackTest_StopRoutine
          sync call scp_EthPhyLoopBackTest_StopR: operation=RP_Sdc_SendInterface_Eth.EthPhyLoopBackTest_StopRoutine, timeout=0.0
        Dsm_u_RC_ETHReadPhyRegister_RequestRoutineResults
          sync call scp_EthReadPhyRegisterInfo_R: operation=RP_Sdc_SendInterface_Eth.EthReadPhyRegisterInfo_Read, timeout=0.0
        Dsm_u_RC_ETHReadPhyRegister_StartRoutine
          sync call scp_EthReadPhyRegister_Start: operation=RP_Sdc_SendInterface_Eth.EthReadPhyRegister_StartRoutine, timeout=0.0
        Dsm_u_RC_ETHResetMACAddress_RequestRoutineResults
          sync call scp_EthResetMACAddressInfo_R: operation=RP_Sdc_SendInterface_Eth.EthResetMACAddressInfo_Read, timeout=0.0
        Dsm_u_RC_ETHResetMACAddress_StartRoutine
          sync call scp_EthResetMACAddress_Start: operation=RP_Sdc_SendInterface_Eth.EthResetMACAddress_StartRoutine, timeout=0.0
        Dsm_u_RC_ETHResetMACLayerStatistic_RequestRoutineResults
          sync call scp_EthResetMACLayerStatisti: operation=RP_Sdc_SendInterface_Eth.EthResetMACLayerStatisticInfo_Read, timeout=0.0
        Dsm_u_RC_ETHResetMACLayerStatistic_StartRoutine
          sync call scp_EthResetMACLayerStatisti: operation=RP_Sdc_SendInterface_Eth.EthResetMACLayerStatistic_StartRoutine, timeout=0.0
        Dsm_u_RC_ETHResetPortConfiguration_RequestRoutineResults
          sync call scp_EthResetPortConfiguratio: operation=RP_Sdc_SendInterface_Eth.EthResetPortConfigurationInfo_Read, timeout=0.0
        Dsm_u_RC_ETHResetPortConfiguration_StartRoutine
          sync call scp_EthResetPortConfiguratio: operation=RP_Sdc_SendInterface_Eth.EthResetPortConfiguration_StartRoutine, timeout=0.0
        Dsm_u_RC_ETHSetPortConfiguration_RequestRoutineResults
          sync call scp_EthSetPortConfigurationI: operation=RP_Sdc_SendInterface_Eth.EthSetPortConfigurationInfo_Read, timeout=0.0
        Dsm_u_RC_ETHSetPortConfiguration_StartRoutine
          sync call scp_EthSetPortConfiguration_: operation=RP_Sdc_SendInterface_Eth.EthSetPortConfiguration_StartRoutine, timeout=0.0
        Dsm_u_RC_ExchangeApplicationRunningArea_StartRoutine: can-enter-exclusive-area=DSM_EXCLUSIVEAREA
          sync call scp_Qsm_GetErrorStatues: operation=RP_Qsm_BlockStartup_FlagOp.Qsm_GetErrorStatues, timeout=0.0
          sync call scp_Qsm_ReadBlock: operation=RP_Qsm_BlockStartup_FlagOp.Qsm_ReadBlock, timeout=0.0
          sync call scp_Qsm_WriteBlock: operation=RP_Qsm_BlockStartup_FlagOp.Qsm_WriteBlock, timeout=0.0
        Dsm_u_RC_LockJTAG_RequestRoutineResults
        Dsm_u_RC_LockJTAG_StartRoutine
        Dsm_u_RC_OTPEnable_RequestRoutineResults
        Dsm_u_RC_OTPEnable_StartRoutine
        Dsm_u_RC_ProgrammingPreconditionCheck_StartRoutine
          data-receive-point-by-arguments:
            access drparg_DE_ESP_VehicleSpeed: accessed-variable=RP_Com_SRI_EspVehSpd.DE_EspVehSpd
          4 x sync call, all with timeout=0.0:
            scp_GetPhyValue: operation=RP_EvAdc_GetValue_VMON_BATT.GetPhyValue
            scp_Qsm_GetErrorStatues: operation=RP_Qsm_BlockSecureUpdateLogOp.Qsm_GetErrorStatues
            scp_Qsm_ReadBlock: operation=RP_Qsm_BlockSecureUpdateLogOp.Qsm_ReadBlock
            scp_Qsm_WriteBlock: operation=RP_Qsm_BlockSecureUpdateLogOp.Qsm_WriteBlock
          written-local-variables:
            access Dsm_IRV_PreCondition_CheckState: accessed-variable=Dsm_IRV_PreCondition_CheckState
        Dsm_u_RC_SDACalibration_RequestRoutineResults
          8 x sync call, all with timeout=0.0:
            scp_CalibrationFlag_Read: operation=RP_Sdc_SendInterface_Calibration.CalibrationFlag_Read
            scp_CameraCaliresultDetails_: operation=RP_Sdc_SendInterface_Calibration.CameraCaliresultDetails_Read
            scp_CameraValue_Read: operation=RP_Sdc_SendInterface_Calibration.CameraValue_Read
            scp_EOLCalResult_Read: operation=RP_Sdc_SendInterface_Calibration.EOLCalResult_Read
            scp_GetErrorStatus: operation=RP_Nvm_SDACalibrationData.GetErrorStatus
            scp_ReadBlock: operation=RP_Nvm_SDACalibrationData.ReadBlock
            scp_SetRamBlockStatus: operation=RP_Nvm_SDACalibrationData.SetRamBlockStatus
            scp_WriteBlock: operation=RP_Nvm_SDACalibrationData.WriteBlock
        Dsm_u_RC_SDACalibration_StartRoutine
          sync call scp_RequestSDACalibration: operation=RP_Sdc_SendInterface_Calibration.RequestSDACalibration, timeout=0.0
          sync call scp_SocSysState_Read: operation=RP_Sdc_SendInterface_Diag.SocSysState_Read, timeout=0.0
        Dsm_u_RC_SaveNvM_RequestRoutineResults
        Dsm_u_RC_SaveNvM_StartRoutine
        Dsm_u_RDBI_AEB_Lastappeared_Read
          sync call scp_GetErrorStatus: operation=RP_Nvm_AEBLastappearFD19.GetErrorStatus, timeout=0.0
          sync call scp_ReadBlock: operation=RP_Nvm_AEBLastappearFD19.ReadBlock, timeout=0.0
        Dsm_u_RDBI_AEB_Lastbutoneappeared_Read
          sync call scp_GetErrorStatus: operation=RP_Nvm_AEBLastbutoneappearFD16.GetErrorStatus, timeout=0.0
          sync call scp_ReadBlock: operation=RP_Nvm_AEBLastbutoneappearFD16.ReadBlock, timeout=0.0
        Dsm_u_RDBI_APPDownloadArea_ConditionCheck
        Dsm_u_RDBI_APPDownloadArea_Read
        Dsm_u_RDBI_AWB_Lastappeared_Read
        Dsm_u_RDBI_AWB_Lastbutoneappeared_Read
          sync call scp_GetErrorStatus: operation=RP_Nvm_AWBLastbutoneappearFD15.GetErrorStatus, timeout=0.0
          sync call scp_ReadBlock: operation=RP_Nvm_AWBLastbutoneappearFD15.ReadBlock, timeout=0.0
        Dsm_u_RDBI_ActiveDiagnosticSessionDataIdentifier_Read
          sync call scp_GetSesCtrlType: operation=RP_Dcm_DCMServices.GetSesCtrlType, timeout=0.0
        Dsm_u_RDBI_BodyHeightWheelHouseEdge_Read
        Dsm_u_RDBI_CalibrationBoardDistance_Read
        Dsm_u_RDBI_CalibrationDataIdentifier_Read
        Dsm_u_RDBI_CalibrationStatus_Read
          sync call scp_CalibrationFlag_Read: operation=RP_Sdc_SendInterface_Calibration.CalibrationFlag_Read, timeout=0.0
          sync call scp_SocSysState_Read: operation=RP_Sdc_SendInterface_Diag.SocSysState_Read, timeout=0.0
        Dsm_u_RDBI_CurrentStaticCalibrationDetails_Read
          sync call scp_CameraCaliresultDetails_: operation=RP_Sdc_SendInterface_Calibration.CameraCaliresultDetails_Read, timeout=0.0
          sync call scp_SocSysState_Read: operation=RP_Sdc_SendInterface_Diag.SocSysState_Read, timeout=0.0
        Dsm_u_RDBI_DiagnosticDefinitionDataIdentifier_Read
        Dsm_u_RDBI_ECUHardwareVersionNumberDataIdentifier_Read
          sync call scp_Qsm_GetErrorStatues: operation=RP_Qsm_BlockPartNumber_SectorOp.Qsm_GetErrorStatues, timeout=0.0
          sync call scp_Qsm_ReadBlock: operation=RP_Qsm_BlockPartNumber_SectorOp.Qsm_ReadBlock, timeout=0.0
        Dsm_u_RDBI_ECUHardwareVersionNumber_Read
        Dsm_u_RDBI_ECUInternalSoftwareVersionNumber_Read
        Dsm_u_RDBI_ECUOperationMode_Read
        Dsm_u_RDBI_ECUSerialNumberDataIdentifier_Read
          sync call scp_GetErrorStatus: operation=RP_Nvm_SerialNumberDataId.GetErrorStatus, timeout=0.0
          sync call scp_ReadBlock: operation=RP_Nvm_SerialNumberDataId.ReadBlock, timeout=0.0
        Dsm_u_RDBI_ECUSoftwareVersionNumberDataIdentifier_Read
        Dsm_u_RDBI_ECUSupplierVoltage_Read
          sync call scp_GetPhyValue: operation=RP_EvAdc_GetValue_VMON_BATT.GetPhyValue, timeout=0.0
        Dsm_u_RDBI_ECUTemperature_Read
          sync call scp_GetPhyValue: operation=RP_EvAdc_GetValue_TMON_SYS1.GetPhyValue, timeout=0.0
          sync call scp_GetPhyValue0: operation=RP_EvAdc_GetValue_TMON_SYS2.GetPhyValue, timeout=0.0
        Dsm_u_RDBI_EOL_CalibrationParameters_Read
          sync call scp_GetErrorStatus: operation=RP_Nvm_EOLCalibrationData.GetErrorStatus, timeout=0.0
          sync call scp_ReadBlock: operation=RP_Nvm_EOLCalibrationData.ReadBlock, timeout=0.0
        Dsm_u_RDBI_EOL_LastResult_Read
        Dsm_u_RDBI_EOL_ModeGate_Read
          sync call scp_Qsm_GetErrorStatues: operation=RP_Qsm_Block_EOLModeGateOP.Qsm_GetErrorStatues, timeout=0.0
          sync call scp_Qsm_ReadBlock: operation=RP_Qsm_Block_EOLModeGateOP.Qsm_ReadBlock, timeout=0.0
        Dsm_u_RDBI_EOL_Previous_EOLResult_Read
        Dsm_u_RDBI_ETH_MAC_Address_Read
          sync call scp_UdsRequest: operation=RP_Sdc_SendInterface_Diag.UdsRequest, timeout=0.0
        Dsm_u_RDBI_ETH_ReadCommunication_ReadyStatus_Read
          sync call scp_UdsRequest: operation=RP_Sdc_SendInterface_Diag.UdsRequest, timeout=0.0
        Dsm_u_RDBI_ETH_ReadMACLayer_Statistics_Read
          sync call scp_UdsRequest: operation=RP_Sdc_SendInterface_Diag.UdsRequest, timeout=0.0
        Dsm_u_RDBI_ETH_ReadMasterSlave_Configures_Read
          sync call scp_UdsRequest: operation=RP_Sdc_SendInterface_Diag.UdsRequest, timeout=0.0
        Dsm_u_RDBI_ETH_ReadPHYLink_State_Read
          sync call scp_UdsRequest: operation=RP_Sdc_SendInterface_Diag.UdsRequest, timeout=0.0
        Dsm_u_RDBI_ETH_ReadPHYSignal_QualityIndex_Read
          sync call scp_UdsRequest: operation=RP_Sdc_SendInterface_Diag.UdsRequest, timeout=0.0
        Dsm_u_RDBI_ETH_ReadPort_Configuration_Read
          sync call scp_UdsRequest: operation=RP_Sdc_SendInterface_Diag.UdsRequest, timeout=0.0
        Dsm_u_RDBI_ETH_Read_NumberOfPorts_Read
          sync call scp_UdsRequest: operation=RP_Sdc_SendInterface_Diag.UdsRequest, timeout=0.0
        Dsm_u_RDBI_FABSwitch_Read
          sync call scp_GetErrorStatus: operation=RP_Nvm_FAB_switch.GetErrorStatus, timeout=0.0
          sync call scp_ReadBlock: operation=RP_Nvm_FAB_switch.ReadBlock, timeout=0.0
        Dsm_u_RDBI_FBLRequirementSpecification_Read
        Dsm_u_RDBI_FBLVersionInformation_Read
        Dsm_u_RDBI_FCW_Lastappeared_Read
          sync call scp_GetErrorStatus: operation=RP_Nvm_FCWLastappearFD17.GetErrorStatus, timeout=0.0
          sync call scp_ReadBlock: operation=RP_Nvm_FCWLastappearFD17.ReadBlock, timeout=0.0
        Dsm_u_RDBI_FCW_Lastbutoneappeared_Read
          sync call scp_GetErrorStatus: operation=RP_Nvm_FCWLastbutoneappearedFD14.GetErrorStatus, timeout=0.0
          sync call scp_ReadBlock: operation=RP_Nvm_FCWLastbutoneappearedFD14.ReadBlock, timeout=0.0
        Dsm_u_RDBI_FunctionSpecificationDataIdentifier_Read
        Dsm_u_RDBI_Fusa_Debug_Status_Read
          sync call scp_GetErrorStatus: operation=RP_Nvm_FS_Debug_Status.GetErrorStatus, timeout=0.0
          sync call scp_ReadBlock: operation=RP_Nvm_FS_Debug_Status.ReadBlock, timeout=0.0
        Dsm_u_RDBI_ImagerTemperature_Read
          sync call scp_SocCpuInfo_Read: operation=RP_Sdc_SendInterface_SocInfo.SocCpuInfo_Read, timeout=0.0
        Dsm_u_RDBI_InternalSocTemperature_Read
          sync call scp_SocCpuInfo_Read: operation=RP_Sdc_SendInterface_SocInfo.SocCpuInfo_Read, timeout=0.0
        Dsm_u_RDBI_InternalTestMode_Read
          read-local-variables:
            access Dsm_IRV_InternalTestMode: accessed-variable=Dsm_IRV_InternalTestMode
        Dsm_u_RDBI_InvalidAttemptCounter_Read
        Dsm_u_RDBI_LaneFunctionConfiguration_Read
          sync call scp_GetErrorStatus: operation=RP_Nvm_LaneFunctionConfiguration.GetErrorStatus, timeout=0.0
          sync call scp_ReadBlock: operation=RP_Nvm_LaneFunctionConfiguration.ReadBlock, timeout=0.0
        Dsm_u_RDBI_MCU_AbankError_Read
        Dsm_u_RDBI_MCU_BbankError_Read
        Dsm_u_RDBI_NetworkInformationDataIdentifier_Read
        Dsm_u_RDBI_OMCalibrationStatus_Read
          4 x sync call, all with timeout=0.0:
            scp_RequestBootSensor: operation=RP_Sdc_SendInterface_SocInfo.RequestBootSensor
            scp_RequestOMSN: operation=RP_Sdc_SendInterface_SocInfo.RequestOMSN
            scp_SocBootSensor_Read: operation=RP_Sdc_SendInterface_SocInfo.SocBootSensor_Read
            scp_SocOMSN_Read: operation=RP_Sdc_SendInterface_SocInfo.SocOMSN_Read
        Dsm_u_RDBI_OMSN_Read
          sync call scp_RequestOMSN: operation=RP_Sdc_SendInterface_SocInfo.RequestOMSN, timeout=0.0
          sync call scp_SocOMSN_Read: operation=RP_Sdc_SendInterface_SocInfo.SocOMSN_Read, timeout=0.0
        Dsm_u_RDBI_PCBASerialNumberDataIdentifier_Read
          sync call scp_GetErrorStatus: operation=RP_Nvm_PCBASerialNumberDataIdentifier.GetErrorStatus, timeout=0.0
          sync call scp_ReadBlock: operation=RP_Nvm_PCBASerialNumberDataIdentifier.ReadBlock, timeout=0.0
        Dsm_u_RDBI_PartNumberDataIdentifier_Read
          sync call scp_Qsm_GetErrorStatues: operation=RP_Qsm_BlockPartNumber_SectorOp.Qsm_GetErrorStatues, timeout=0.0
          sync call scp_Qsm_ReadBlock: operation=RP_Qsm_BlockPartNumber_SectorOp.Qsm_ReadBlock, timeout=0.0
        Dsm_u_RDBI_ProjectID_Read
        Dsm_u_RDBI_SDA_LastResults_Read
        Dsm_u_RDBI_SecureUpdateLog_Read
          sync call scp_Qsm_GetErrorStatues: operation=RP_Qsm_BlockSecureUpdateLogOp.Qsm_GetErrorStatues, timeout=0.0
          sync call scp_Qsm_ReadBlock: operation=RP_Qsm_BlockSecureUpdateLogOp.Qsm_ReadBlock, timeout=0.0
        Dsm_u_RDBI_SocBootSensor_Read
          4 x sync call, all with timeout=0.0:
            scp_RequestBootSensor: operation=RP_Sdc_SendInterface_SocInfo.RequestBootSensor
            scp_RequestOMSN: operation=RP_Sdc_SendInterface_SocInfo.RequestOMSN
            scp_SocBootSensor_Read: operation=RP_Sdc_SendInterface_SocInfo.SocBootSensor_Read
            scp_SocOMSN_Read: operation=RP_Sdc_SendInterface_SocInfo.SocOMSN_Read
        Dsm_u_RDBI_SocResetControl_Read
          read-local-variables:
            access Dsm_IRV_SocResetControlState: accessed-variable=Dsm_IRV_SocResetControlState
        Dsm_u_RDBI_SocSoftwareNumberDataIdentifier_Read
        Dsm_u_RDBI_SocSoftwareVersion_Read
          sync call scp_UdsRequest: operation=RP_Sdc_SendInterface_Diag.UdsRequest, timeout=0.0
        Dsm_u_RDBI_SocSupplierSoftwareNumber_Read
          sync call scp_UdsRequest: operation=RP_Sdc_SendInterface_Diag.UdsRequest, timeout=0.0
        Dsm_u_RDBI_SoftwareNumber_Read
        Dsm_u_RDBI_SystemSupplierIdentifier_Read
          sync call scp_Qsm_GetErrorStatues: operation=RP_Qsm_BlockPartNumber_SectorOp.Qsm_GetErrorStatues, timeout=0.0
          sync call scp_Qsm_ReadBlock: operation=RP_Qsm_BlockPartNumber_SectorOp.Qsm_ReadBlock, timeout=0.0
        Dsm_u_RDBI_TLASwitch_Read
          sync call scp_GetErrorStatus: operation=RP_Nvm_TLA_switch.GetErrorStatus, timeout=0.0
          sync call scp_ReadBlock: operation=RP_Nvm_TLA_switch.ReadBlock, timeout=0.0
        Dsm_u_RDBI_TSRSwitch_Read
          sync call scp_GetErrorStatus: operation=RP_Nvm_TSR_switch.GetErrorStatus, timeout=0.0
          sync call scp_ReadBlock: operation=RP_Nvm_TSR_switch.ReadBlock, timeout=0.0
        Dsm_u_RDBI_VINDataIdentifier_Read
          sync call scp_GetErrorStatus: operation=RP_Nvm_VINDataIdentifier.GetErrorStatus, timeout=0.0
          sync call scp_ReadBlock: operation=RP_Nvm_VINDataIdentifier.ReadBlock, timeout=0.0
        Dsm_u_RDBI_VehicleType_Read
          sync call scp_GetErrorStatus: operation=RP_Nvm_Vehicletype.GetErrorStatus, timeout=0.0
          sync call scp_ReadBlock: operation=RP_Nvm_Vehicletype.ReadBlock, timeout=0.0
        Dsm_u_RDBI_applicationSoftwareFingerprintDataIdentifier_Read
        Dsm_u_SA_Level1_CompareKey
        Dsm_u_SA_Level1_GetAttemptCounter
        Dsm_u_SA_Level1_GetSeed
        Dsm_u_SA_Level1_SetAttemptCounter
          4 x sync call, all with timeout=0.0:
            scp_GetErrorStatus: operation=RP_Nvm_Security_AttemptCount.GetErrorStatus
            scp_ReadBlock: operation=RP_Nvm_Security_AttemptCount.ReadBlock
            scp_SetRamBlockStatus: operation=RP_Nvm_Security_AttemptCount.SetRamBlockStatus
            scp_WriteBlock: operation=RP_Nvm_Security_AttemptCount.WriteBlock
        Dsm_u_ServiceRequestSupplierNotification_Confirmation
        Dsm_u_ServiceRequestSupplierNotification_Indication
          sync call scp_GetPhyValue: operation=RP_EvAdc_GetValue_VMON_BATT.GetPhyValue, timeout=0.0
        Dsm_u_WDBI_ECUHardwareVersionNumberDataIdentifier_Write: can-enter-exclusive-area=DSM_EXCLUSIVEAREA
          sync call scp_Qsm_GetErrorStatues: operation=RP_Qsm_BlockPartNumber_SectorOp.Qsm_GetErrorStatues, timeout=0.0
          sync call scp_Qsm_WriteBlock: operation=RP_Qsm_BlockPartNumber_SectorOp.Qsm_WriteBlock, timeout=0.0
        Dsm_u_WDBI_ECUOperationMode_Write
        Dsm_u_WDBI_ECUSerialNumberDataIdentifier_Write: can-enter-exclusive-area=DSM_EXCLUSIVEAREA
          sync call scp_GetErrorStatus: operation=RP_Nvm_SerialNumberDataId.GetErrorStatus, timeout=0.0
          sync call scp_SetRamBlockStatus: operation=RP_Nvm_SerialNumberDataId.SetRamBlockStatus, timeout=0.0
          sync call scp_WriteBlock: operation=RP_Nvm_SerialNumberDataId.WriteBlock, timeout=0.0
        Dsm_u_WDBI_EOL_ModeGate_Write: can-enter-exclusive-area=DSM_EXCLUSIVEAREA
          sync call scp_Qsm_GetErrorStatues: operation=RP_Qsm_Block_EOLModeGateOP.Qsm_GetErrorStatues, timeout=0.0
          sync call scp_Qsm_WriteBlock: operation=RP_Qsm_Block_EOLModeGateOP.Qsm_WriteBlock, timeout=0.0
        Dsm_u_WDBI_FABSwitch_Write: can-enter-exclusive-area=DSM_EXCLUSIVEAREA
          sync call scp_GetErrorStatus: operation=RP_Nvm_FAB_switch.GetErrorStatus, timeout=0.0
          sync call scp_SetRamBlockStatus: operation=RP_Nvm_FAB_switch.SetRamBlockStatus, timeout=0.0
          sync call scp_WriteBlock: operation=RP_Nvm_FAB_switch.WriteBlock, timeout=0.0
        Dsm_u_WDBI_Fusa_Debug_Status_Write
          sync call scp_GetErrorStatus: operation=RP_Nvm_FS_Debug_Status.GetErrorStatus, timeout=0.0
          sync call scp_SetRamBlockStatus: operation=RP_Nvm_FS_Debug_Status.SetRamBlockStatus, timeout=0.0
          sync call scp_WriteBlock: operation=RP_Nvm_FS_Debug_Status.WriteBlock, timeout=0.0
        Dsm_u_WDBI_InternalTestMode_Write
          data-send-points:
            access dsp_DE_InternalTestMode: accessed-variable=PP_Dsm_SRI_InternalTestMode.DE_InternalTestMode
          written-local-variables:
            access Dsm_IRV_InternalTestMode: accessed-variable=Dsm_IRV_InternalTestMode
        Dsm_u_WDBI_LaneFunctionConfiguration_Write: can-enter-exclusive-area=DSM_EXCLUSIVEAREA
          sync call scp_GetErrorStatus: operation=RP_Nvm_LaneFunctionConfiguration.GetErrorStatus, timeout=0.0
          sync call scp_SetRamBlockStatus: operation=RP_Nvm_LaneFunctionConfiguration.SetRamBlockStatus, timeout=0.0
          sync call scp_WriteBlock: operation=RP_Nvm_LaneFunctionConfiguration.WriteBlock, timeout=0.0
        Dsm_u_WDBI_PCBASerialNumberDataIdentifier_Write: can-enter-exclusive-area=DSM_EXCLUSIVEAREA
          sync call scp_GetErrorStatus: operation=RP_Nvm_PCBASerialNumberDataIdentifier.GetErrorStatus, timeout=0.0
          sync call scp_SetRamBlockStatus: operation=RP_Nvm_PCBASerialNumberDataIdentifier.SetRamBlockStatus, timeout=0.0
          sync call scp_WriteBlock: operation=RP_Nvm_PCBASerialNumberDataIdentifier.WriteBlock, timeout=0.0
        Dsm_u_WDBI_PartNumberDataIdentifier_Write: can-enter-exclusive-area=DSM_EXCLUSIVEAREA
          sync call scp_Qsm_GetErrorStatues: operation=RP_Qsm_BlockPartNumber_SectorOp.Qsm_GetErrorStatues, timeout=0.0
          sync call scp_Qsm_WriteBlock: operation=RP_Qsm_BlockPartNumber_SectorOp.Qsm_WriteBlock, timeout=0.0
        Dsm_u_WDBI_SocResetControl_Write
          data-send-points:
            access dsp_DE_SocRersetControlState: accessed-variable=PP_Dsm_SRI_SocResetControlState.DE_SocRersetControlState
          written-local-variables:
            access Dsm_IRV_SocResetControlState: accessed-variable=Dsm_IRV_SocResetControlState
        Dsm_u_WDBI_SystemSupplierIdentifier_Write: can-enter-exclusive-area=DSM_EXCLUSIVEAREA
          sync call scp_Qsm_GetErrorStatues: operation=RP_Qsm_BlockPartNumber_SectorOp.Qsm_GetErrorStatues, timeout=0.0
          sync call scp_Qsm_WriteBlock: operation=RP_Qsm_BlockPartNumber_SectorOp.Qsm_WriteBlock, timeout=0.0
        Dsm_u_WDBI_TLASwitch_Write: can-enter-exclusive-area=DSM_EXCLUSIVEAREA
          sync call scp_GetErrorStatus: operation=RP_Nvm_TLA_switch.GetErrorStatus, timeout=0.0
          sync call scp_SetRamBlockStatus: operation=RP_Nvm_TLA_switch.SetRamBlockStatus, timeout=0.0
          sync call scp_WriteBlock: operation=RP_Nvm_TLA_switch.WriteBlock, timeout=0.0
        Dsm_u_WDBI_TSRSwitch_Write: can-enter-exclusive-area=DSM_EXCLUSIVEAREA
          sync call scp_GetErrorStatus: operation=RP_Nvm_TSR_switch.GetErrorStatus, timeout=0.0
          sync call scp_SetRamBlockStatus: operation=RP_Nvm_TSR_switch.SetRamBlockStatus, timeout=0.0
          sync call scp_WriteBlock: operation=RP_Nvm_TSR_switch.WriteBlock, timeout=0.0
        Dsm_u_WDBI_VINDataIdentifier_Write: can-enter-exclusive-area=DSM_EXCLUSIVEAREA
          sync call scp_GetErrorStatus: operation=RP_Nvm_VINDataIdentifier.GetErrorStatus, timeout=0.0
          sync call scp_SetRamBlockStatus: operation=RP_Nvm_VINDataIdentifier.SetRamBlockStatus, timeout=0.0
          sync call scp_WriteBlock: operation=RP_Nvm_VINDataIdentifier.WriteBlock, timeout=0.0
        Dsm_u_WDBI_VehicleType_Write: can-enter-exclusive-area=DSM_EXCLUSIVEAREA
          sync call scp_GetErrorStatus: operation=RP_Nvm_Vehicletype.GetErrorStatus, timeout=0.0
          sync call scp_SetRamBlockStatus: operation=RP_Nvm_Vehicletype.SetRamBlockStatus, timeout=0.0
          sync call scp_WriteBlock: operation=RP_Nvm_Vehicletype.WriteBlock, timeout=0.0
        Dsm_v_Init
        Dsm_v_MainFunction: can-enter-exclusive-area=DSM_EXCLUSIVEAREA
          read-local-variables:
            access Dsm_IRV_PreCondition_CheckState: accessed-variable=Dsm_IRV_PreCondition_CheckState
          4 x sync call, all with timeout=0.0:
            scp_Cdm_GetErrorStatus: operation=RP_Cdm_DsmBlockOp.Cdm_GetErrorStatus
            scp_Cdm_ReadBlock: operation=RP_Cdm_DsmBlockOp.Cdm_ReadBlock
            scp_Cdm_WriteBlock: operation=RP_Cdm_DsmBlockOp.Cdm_WriteBlock
            scp_GetTimeStampMs: operation=RP_Time_GlobalTime.GetTimeStampMs
  swc implementation DsmImpl: programming-language=C, sw-version=1.0.0, vendor-id=0, behavior=Dsm_IB
    code-descriptors:
      code CodeGen: artifact-descriptors=[{short-label=SWSRC, category=SWSRC}, {short-label=SWHDR, category=SWHDR}]
    resource consumption Resource
      memory section CODE: sw-addrmethod=CODE
      memory section VAR_UNSPECIFIED: sw-addrmethod=VAR_CLEARED
  sender receiver interface SRI_DsmSocResetcontrolState
    data DE_SocRersetControlState: type=uint8, init-value=SOCRESET_DISABLE:0
  sender receiver interface SRI_InternalTestMode
    data DE_InternalTestMode: type=uint8
